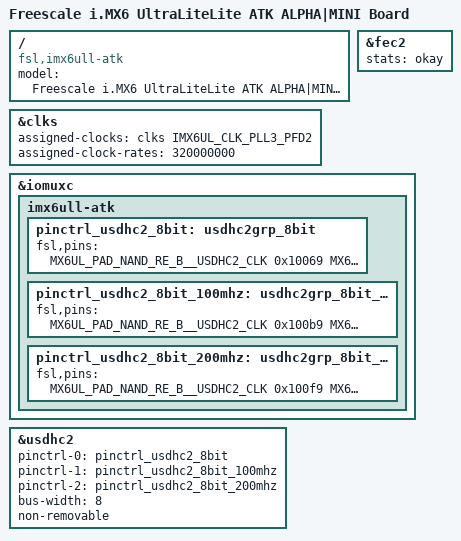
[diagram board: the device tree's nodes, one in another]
// SPDX-License-Identifier: (GPL-2.0 OR MIT)
//
// Copyright (C) 2016 Freescale Semiconductor, Inc.

/dts-v1/;

#include "imx6ull.dtsi"
#include "imx6ul-14x14-evk.dtsi"

/ {
	model = "Freescale i.MX6 UltraLiteLite ATK ALPHA|MINI Board";
	compatible = "fsl,imx6ull-atk", "fsl,imx6ull";
};

&clks {
	assigned-clocks = <&clks IMX6UL_CLK_PLL3_PFD2>;
	assigned-clock-rates = <320000000>;
};

/*/delete-node/ &fec1; */

&fec2 {
	stats = "okay";
};

&iomuxc{
	imx6ull-atk{
		pinctrl_usdhc2_8bit: usdhc2grp_8bit {
			fsl,pins = <
				MX6UL_PAD_NAND_RE_B__USDHC2_CLK     0x10069
				MX6UL_PAD_NAND_WE_B__USDHC2_CMD     0x17059
				MX6UL_PAD_NAND_DATA00__USDHC2_DATA0 0x17059
				MX6UL_PAD_NAND_DATA01__USDHC2_DATA1 0x17059
				MX6UL_PAD_NAND_DATA02__USDHC2_DATA2 0x17059
				MX6UL_PAD_NAND_DATA03__USDHC2_DATA3 0x17059
				MX6UL_PAD_NAND_DATA04__USDHC2_DATA4 0x17059
				MX6UL_PAD_NAND_DATA05__USDHC2_DATA5 0x17059
				MX6UL_PAD_NAND_DATA06__USDHC2_DATA6 0x17059
				MX6UL_PAD_NAND_DATA07__USDHC2_DATA7 0x17059
			>;
		};

		pinctrl_usdhc2_8bit_100mhz: usdhc2grp_8bit_100mhz {
			fsl,pins = <
				MX6UL_PAD_NAND_RE_B__USDHC2_CLK     0x100b9
				MX6UL_PAD_NAND_WE_B__USDHC2_CMD     0x170b9
				MX6UL_PAD_NAND_DATA00__USDHC2_DATA0 0x170b9
				MX6UL_PAD_NAND_DATA01__USDHC2_DATA1 0x170b9
				MX6UL_PAD_NAND_DATA02__USDHC2_DATA2 0x170b9
				MX6UL_PAD_NAND_DATA03__USDHC2_DATA3 0x170b9
				MX6UL_PAD_NAND_DATA04__USDHC2_DATA4 0x170b9
				MX6UL_PAD_NAND_DATA05__USDHC2_DATA5 0x170b9
				MX6UL_PAD_NAND_DATA06__USDHC2_DATA6 0x170b9
				MX6UL_PAD_NAND_DATA07__USDHC2_DATA7 0x170b9
			>;
		};

		pinctrl_usdhc2_8bit_200mhz: usdhc2grp_8bit_200mhz {
			fsl,pins = <
				MX6UL_PAD_NAND_RE_B__USDHC2_CLK     0x100f9
				MX6UL_PAD_NAND_WE_B__USDHC2_CMD     0x170f9
				MX6UL_PAD_NAND_DATA00__USDHC2_DATA0 0x170f9
				MX6UL_PAD_NAND_DATA01__USDHC2_DATA1 0x170f9
				MX6UL_PAD_NAND_DATA02__USDHC2_DATA2 0x170f9
				MX6UL_PAD_NAND_DATA03__USDHC2_DATA3 0x170f9
				MX6UL_PAD_NAND_DATA04__USDHC2_DATA4 0x170f9
				MX6UL_PAD_NAND_DATA05__USDHC2_DATA5 0x170f9
				MX6UL_PAD_NAND_DATA06__USDHC2_DATA6 0x170f9
				MX6UL_PAD_NAND_DATA07__USDHC2_DATA7 0x170f9
			>;
		};
	};

};

&usdhc2 {
	pinctrl-names = "default", "state_100mhz", "state_200mhz";
	pinctrl-0 = <&pinctrl_usdhc2_8bit>;
	pinctrl-1 = <&pinctrl_usdhc2_8bit_100mhz>;
	pinctrl-2 = <&pinctrl_usdhc2_8bit_200mhz>;
	bus-width = <8>;
	non-removable;
	status = "okay";
};

